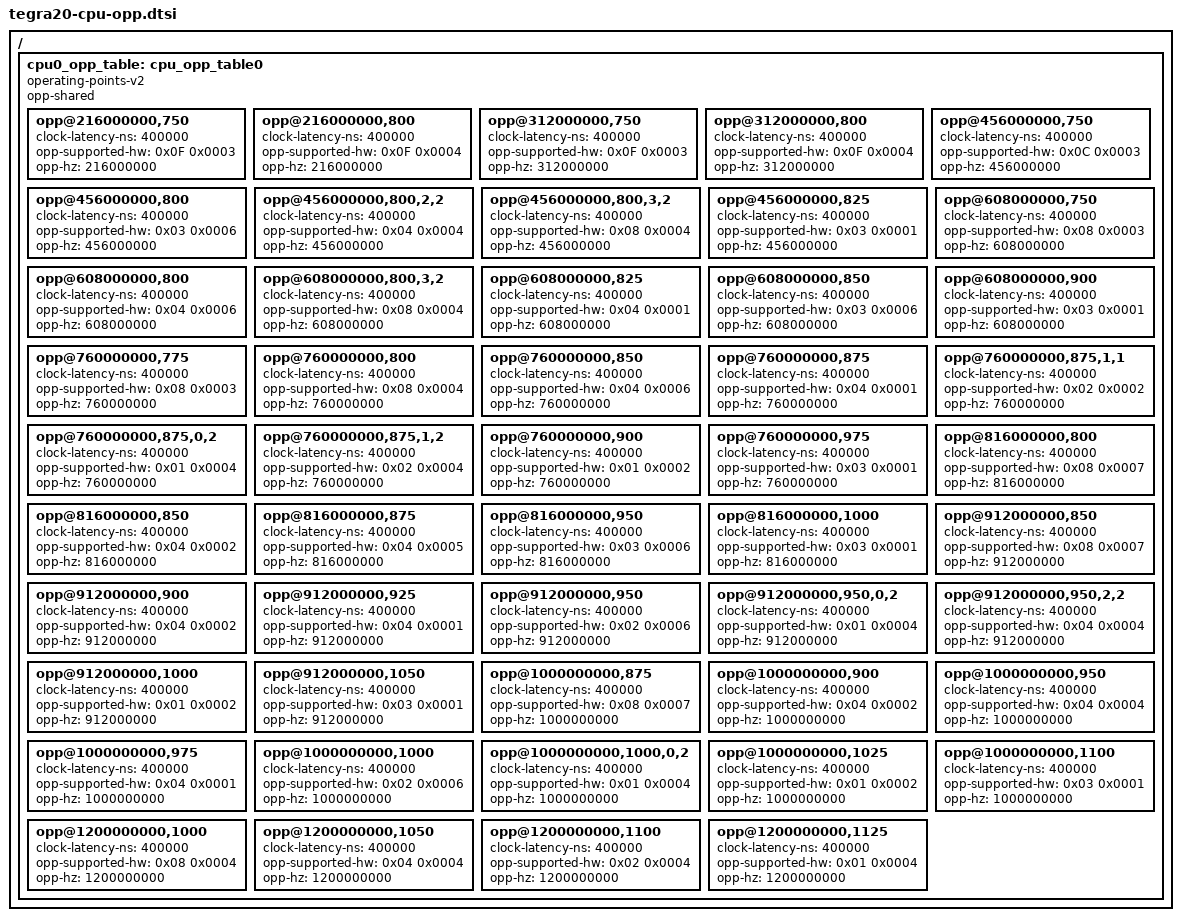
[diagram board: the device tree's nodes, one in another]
// SPDX-License-Identifier: GPL-2.0

/ {
	cpu0_opp_table: cpu_opp_table0 {
		compatible = "operating-points-v2";
		opp-shared;

		opp@216000000,750 {
			clock-latency-ns = <400000>;
			opp-supported-hw = <0x0F 0x0003>;
			opp-hz = /bits/ 64 <216000000>;
		};

		opp@216000000,800 {
			clock-latency-ns = <400000>;
			opp-supported-hw = <0x0F 0x0004>;
			opp-hz = /bits/ 64 <216000000>;
		};

		opp@312000000,750 {
			clock-latency-ns = <400000>;
			opp-supported-hw = <0x0F 0x0003>;
			opp-hz = /bits/ 64 <312000000>;
		};

		opp@312000000,800 {
			clock-latency-ns = <400000>;
			opp-supported-hw = <0x0F 0x0004>;
			opp-hz = /bits/ 64 <312000000>;
		};

		opp@456000000,750 {
			clock-latency-ns = <400000>;
			opp-supported-hw = <0x0C 0x0003>;
			opp-hz = /bits/ 64 <456000000>;
		};

		opp@456000000,800 {
			clock-latency-ns = <400000>;
			opp-supported-hw = <0x03 0x0006>;
			opp-hz = /bits/ 64 <456000000>;
		};

		opp@456000000,800,2,2 {
			clock-latency-ns = <400000>;
			opp-supported-hw = <0x04 0x0004>;
			opp-hz = /bits/ 64 <456000000>;
		};

		opp@456000000,800,3,2 {
			clock-latency-ns = <400000>;
			opp-supported-hw = <0x08 0x0004>;
			opp-hz = /bits/ 64 <456000000>;
		};

		opp@456000000,825 {
			clock-latency-ns = <400000>;
			opp-supported-hw = <0x03 0x0001>;
			opp-hz = /bits/ 64 <456000000>;
		};

		opp@608000000,750 {
			clock-latency-ns = <400000>;
			opp-supported-hw = <0x08 0x0003>;
			opp-hz = /bits/ 64 <608000000>;
		};

		opp@608000000,800 {
			clock-latency-ns = <400000>;
			opp-supported-hw = <0x04 0x0006>;
			opp-hz = /bits/ 64 <608000000>;
		};

		opp@608000000,800,3,2 {
			clock-latency-ns = <400000>;
			opp-supported-hw = <0x08 0x0004>;
			opp-hz = /bits/ 64 <608000000>;
		};

		opp@608000000,825 {
			clock-latency-ns = <400000>;
			opp-supported-hw = <0x04 0x0001>;
			opp-hz = /bits/ 64 <608000000>;
		};

		opp@608000000,850 {
			clock-latency-ns = <400000>;
			opp-supported-hw = <0x03 0x0006>;
			opp-hz = /bits/ 64 <608000000>;
		};

		opp@608000000,900 {
			clock-latency-ns = <400000>;
			opp-supported-hw = <0x03 0x0001>;
			opp-hz = /bits/ 64 <608000000>;
		};

		opp@760000000,775 {
			clock-latency-ns = <400000>;
			opp-supported-hw = <0x08 0x0003>;
			opp-hz = /bits/ 64 <760000000>;
		};

		opp@760000000,800 {
			clock-latency-ns = <400000>;
			opp-supported-hw = <0x08 0x0004>;
			opp-hz = /bits/ 64 <760000000>;
		};

		opp@760000000,850 {
			clock-latency-ns = <400000>;
			opp-supported-hw = <0x04 0x0006>;
			opp-hz = /bits/ 64 <760000000>;
		};

		opp@760000000,875 {
			clock-latency-ns = <400000>;
			opp-supported-hw = <0x04 0x0001>;
			opp-hz = /bits/ 64 <760000000>;
		};

		opp@760000000,875,1,1 {
			clock-latency-ns = <400000>;
			opp-supported-hw = <0x02 0x0002>;
			opp-hz = /bits/ 64 <760000000>;
		};

		opp@760000000,875,0,2 {
			clock-latency-ns = <400000>;
			opp-supported-hw = <0x01 0x0004>;
			opp-hz = /bits/ 64 <760000000>;
		};

		opp@760000000,875,1,2 {
			clock-latency-ns = <400000>;
			opp-supported-hw = <0x02 0x0004>;
			opp-hz = /bits/ 64 <760000000>;
		};

		opp@760000000,900 {
			clock-latency-ns = <400000>;
			opp-supported-hw = <0x01 0x0002>;
			opp-hz = /bits/ 64 <760000000>;
		};

		opp@760000000,975 {
			clock-latency-ns = <400000>;
			opp-supported-hw = <0x03 0x0001>;
			opp-hz = /bits/ 64 <760000000>;
		};

		opp@816000000,800 {
			clock-latency-ns = <400000>;
			opp-supported-hw = <0x08 0x0007>;
			opp-hz = /bits/ 64 <816000000>;
		};

		opp@816000000,850 {
			clock-latency-ns = <400000>;
			opp-supported-hw = <0x04 0x0002>;
			opp-hz = /bits/ 64 <816000000>;
		};

		opp@816000000,875 {
			clock-latency-ns = <400000>;
			opp-supported-hw = <0x04 0x0005>;
			opp-hz = /bits/ 64 <816000000>;
		};

		opp@816000000,950 {
			clock-latency-ns = <400000>;
			opp-supported-hw = <0x03 0x0006>;
			opp-hz = /bits/ 64 <816000000>;
		};

		opp@816000000,1000 {
			clock-latency-ns = <400000>;
			opp-supported-hw = <0x03 0x0001>;
			opp-hz = /bits/ 64 <816000000>;
		};

		opp@912000000,850 {
			clock-latency-ns = <400000>;
			opp-supported-hw = <0x08 0x0007>;
			opp-hz = /bits/ 64 <912000000>;
		};

		opp@912000000,900 {
			clock-latency-ns = <400000>;
			opp-supported-hw = <0x04 0x0002>;
			opp-hz = /bits/ 64 <912000000>;
		};

		opp@912000000,925 {
			clock-latency-ns = <400000>;
			opp-supported-hw = <0x04 0x0001>;
			opp-hz = /bits/ 64 <912000000>;
		};

		opp@912000000,950 {
			clock-latency-ns = <400000>;
			opp-supported-hw = <0x02 0x0006>;
			opp-hz = /bits/ 64 <912000000>;
		};

		opp@912000000,950,0,2 {
			clock-latency-ns = <400000>;
			opp-supported-hw = <0x01 0x0004>;
			opp-hz = /bits/ 64 <912000000>;
		};

		opp@912000000,950,2,2 {
			clock-latency-ns = <400000>;
			opp-supported-hw = <0x04 0x0004>;
			opp-hz = /bits/ 64 <912000000>;
		};

		opp@912000000,1000 {
			clock-latency-ns = <400000>;
			opp-supported-hw = <0x01 0x0002>;
			opp-hz = /bits/ 64 <912000000>;
		};

		opp@912000000,1050 {
			clock-latency-ns = <400000>;
			opp-supported-hw = <0x03 0x0001>;
			opp-hz = /bits/ 64 <912000000>;
		};

		opp@1000000000,875 {
			clock-latency-ns = <400000>;
			opp-supported-hw = <0x08 0x0007>;
			opp-hz = /bits/ 64 <1000000000>;
		};

		opp@1000000000,900 {
			clock-latency-ns = <400000>;
			opp-supported-hw = <0x04 0x0002>;
			opp-hz = /bits/ 64 <1000000000>;
		};

		opp@1000000000,950 {
			clock-latency-ns = <400000>;
			opp-supported-hw = <0x04 0x0004>;
			opp-hz = /bits/ 64 <1000000000>;
		};

		opp@1000000000,975 {
			clock-latency-ns = <400000>;
			opp-supported-hw = <0x04 0x0001>;
			opp-hz = /bits/ 64 <1000000000>;
		};

		opp@1000000000,1000 {
			clock-latency-ns = <400000>;
			opp-supported-hw = <0x02 0x0006>;
			opp-hz = /bits/ 64 <1000000000>;
		};

		opp@1000000000,1000,0,2 {
			clock-latency-ns = <400000>;
			opp-supported-hw = <0x01 0x0004>;
			opp-hz = /bits/ 64 <1000000000>;
		};

		opp@1000000000,1025 {
			clock-latency-ns = <400000>;
			opp-supported-hw = <0x01 0x0002>;
			opp-hz = /bits/ 64 <1000000000>;
		};

		opp@1000000000,1100 {
			clock-latency-ns = <400000>;
			opp-supported-hw = <0x03 0x0001>;
			opp-hz = /bits/ 64 <1000000000>;
		};

		opp@1200000000,1000 {
			clock-latency-ns = <400000>;
			opp-supported-hw = <0x08 0x0004>;
			opp-hz = /bits/ 64 <1200000000>;
		};

		opp@1200000000,1050 {
			clock-latency-ns = <400000>;
			opp-supported-hw = <0x04 0x0004>;
			opp-hz = /bits/ 64 <1200000000>;
		};

		opp@1200000000,1100 {
			clock-latency-ns = <400000>;
			opp-supported-hw = <0x02 0x0004>;
			opp-hz = /bits/ 64 <1200000000>;
		};

		opp@1200000000,1125 {
			clock-latency-ns = <400000>;
			opp-supported-hw = <0x01 0x0004>;
			opp-hz = /bits/ 64 <1200000000>;
		};
	};
};
